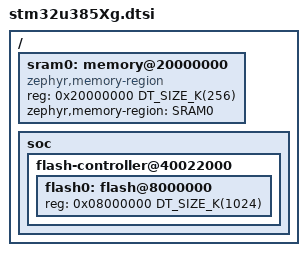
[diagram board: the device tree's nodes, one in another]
/*
 * Copyright (c) 2025 STMicroelectronics
 *
 * SPDX-License-Identifier: Apache-2.0
 */

#include <st/u3/stm32u385.dtsi>

/ {
	sram0: memory@20000000 {
		compatible = "zephyr,memory-region", "mmio-sram";
		/* SRAM1 + SRAM2 */
		/* 192K + 64K */
		reg = <0x20000000 DT_SIZE_K(256)>;
		zephyr,memory-region = "SRAM0";
	};

	soc {
		flash-controller@40022000 {
			flash0: flash@8000000 {
				reg = <0x08000000 DT_SIZE_K(1024)>;
			};
		};
	};
};
